# tle984x register map
Vendor: Infineon; File version: 1.9.5
CPU: CM0 r2p1, little endian, no MPU, no FPU, 2 interrupt priority bits
Registers are 32-bit, read-write, reset 0x0 unless marked. A register's access mark holds for its fields unless they carry their own. Offsets are from the block's base; [hi:lo] are bit positions; {n}, {i} and the like mark numbered series; 'fields as' and 'values as' point back to an identical list.

## CCU6 — Capture/Compare Unit 6 (CCU6) registers
Base 0x4000C000
0x00 CC63R 16-bit ro — Capture/compare for channel CC63 register
  [15:0] CCV — Channel CC63 compare value low byte
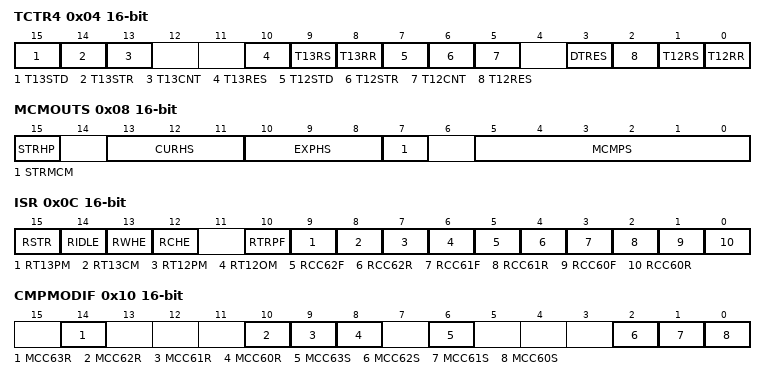
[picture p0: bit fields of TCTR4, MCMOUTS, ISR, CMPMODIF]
0x04 TCTR4 16-bit — Timer control 4 register
  [15] T13STD wo — Timer T13 shadow transfer disable
    0=No_action; 1=STE13_reset (STE13 is reset without triggering the shadow transfer)
  [14] T13STR wo — Timer T13 shadow transfer request
    0=No_action; 1=STE13_set (STE13 is set, enabling the shadow transfer)
  [13] T13CNT wo — Timer T13 count event
    0=No_action; 1=Count (If enabled (PISEL2), timer T13 counts one step)
  [10] T13RES wo — Timer T13 reset
    0=No effect on T13; 1=Zero (The T13 counter register is reset to zero. The switching of the output signals is according to the switching rules. Setting of T13RES has no impact on bit T13R)
  [9] T13RS wo — Timer T13 run set
    0=No_influence (T13R is not influenced); 1=T13R_set (T13R is set, T13 counts)
  [8] T13RR wo — Timer T13 run reset
    0=No_influence (T13R is not influenced); 1=T13R_cleared (T13R is cleared, T13 stops counting)
  [7] T12STD wo — Timer T12 shadow transfer disable
    0=No_action; 1=STE12_reset (STE12 is reset without triggering the shadow transfer)
  [6] T12STR wo — Timer T12 shadow transfer request
    0=No_action; 1=STE12_set (STE12 is set, enabling the shadow transfer)
  [5] T12CNT wo — Timer T12 count event
    0=No_action; 1=Count (If enabled (PISEL2), timer T12 counts one step)
  [3] DTRES wo — Dead-time counter reset
    0=No effect on the dead-time counters; 1=Zero (The three dead-time counter channels are reset to zero)
  [2] T12RES wo — Timer T12 reset
    0=No effect on T12; 1=Zero (The T12 counter register is reset to zero. The switching of the output signals is according to the switching rules; setting of T12RES has no impact on bit T12R)
  [1] T12RS wo — Timer T12 run set
    0=No_influence (T12R is not influenced); 1=T12R_set (T12R is set, T12 counts)
  [0] T12RR wo — Timer T12 run reset
    0=No_influence (T12R is not influenced); 1=T12R_cleared (T12R is cleared, T12 stops counting)
0x08 MCMOUTS 16-bit — Multi-channel mode output shadow register
  [15] STRHP wo — Shadow transfer request for the Hall pattern
    0=By_hardware (The bit fields CURH and EXPH are updated according to the defined hardware action. The write access to bit fields CURHS and EXPHS does not modify the bit fields CURH and EXPH); 1=By_software (The bit fields CURH and EXPH are updated by the value written to the bit fields CURHS and EXPHS)
  [13:11] CURHS — Current Hall pattern shadow
  [10:8] EXPHS — Expected Hall pattern shadow
  [7] STRMCM wo — Shadow transfer request for MCMPS
    0=By_hardware (Bit field MCMP is updated according to the defined hardware action. The write access to bit field MCMPS does not modify bit field MCMP); 1=By_software (Bit field MCMP is updated by the value written to bit field MCMPS)
  [5:0] MCMPS — Multi-channel PWM pattern shadow
0x0C ISR 16-bit — Capture/compare interrupt status reset register
  [15] RSTR wo — Reset STR flag
    0=No_action; 1=Reset (Bit STR in register IS will be reset)
  [14] RIDLE wo — Reset IDLE flag
    0=No_action; 1=Reset (Bit IDLE in register IS will be reset)
  [13] RWHE wo — Reset wrong Hall event flag
    0=No_action; 1=Reset (Bit WHE in register IS will be reset)
  [12] RCHE wo — Reset correct Hall event flag
    0=No_action; 1=Reset (Bit CHE in register IS will be reset)
  [10] RTRPF wo — Reset trap flag
    0=No_action; 1=Reset (Bit TRPF in register IS will be reset (not taken into account while input CTRAP= 0 and TRPPEN = 1))
  [9] RT13PM wo — Reset timer T13 period-Match flag
    0=No_action; 1=Reset (Bit T13PM in register IS will be reset)
  [8] RT13CM wo — Reset timer T13 compare-match flag
    0=No_action; 1=Reset (Bit T13CM in register IS will be reset)
  [7] RT12PM wo — Reset timer T12 period-match flag
    0=No_action; 1=Reset (Bit T12PM in register IS will be reset)
  [6] RT12OM wo — Reset timer T12 one-match flag
    0=No_action; 1=Reset (Bit T12OM in register IS will be reset)
  [5] RCC62F wo — Reset capture, compare-match falling edge flag
    0=No_action; 1=Reset (Bit CC62F in register IS will be reset)
  [4] RCC62R wo — Reset capture, compare-match rising edge flag
    0=No_action; 1=Reset (Bit CC62R in register IS will be reset)
  [3] RCC61F wo — Reset capture, compare-match falling edge flag
    0=No_action; 1=Reset (Bit CC61F in register IS will be reset)
  [2] RCC61R wo — Reset capture, compare-match rising edge Flag
    0=No_action; 1=Reset (Bit CC61R in register IS will be reset)
  [1] RCC60F wo — Reset capture, compare-match falling edge flag
    0=No_action; 1=Reset (Bit CC60F in register IS will be reset)
  [0] RCC60R wo — Reset capture, compare-match rising edge flag
    0=No_action; 1=Reset (Bit CC60R in register IS will be reset)
0x10 CMPMODIF 16-bit — Compare state modification register
  [14] MCC63R wo — Capture/compare status modification bits (reset)
  [10] MCC62R wo — Capture/compare status modification bit 2 (reset)
  [9] MCC61R wo — Capture/compare status modification bit 1 (reset)
  [8] MCC60R wo — Capture/compare status modification bit 0 (reset)
  [6] MCC63S wo — Capture/compare status modification bits (set)
  [2] MCC62S wo — Capture/compare status modification bit 2 (set)
  [1] MCC61S wo — Capture/compare status modification bit 1 (set)
  [0] MCC60S wo — Capture/compare status modification bit 0 (set)
0x14 CC60SR 16-bit — Capture/compare shadow register for channel CC60 register
  [15:0] CCS — Shadow register for channel 0 capture/compare value
0x18 CC61SR 16-bit — Capture/compare shadow register for channel CC61 register
  [15:0] CCS — Shadow register for channel 1 capture/compare value
0x1C CC62SR 16-bit — Capture/compare shadow register for channel CC62 register
  [15:0] CCS — Shadow register for channel 2 capture/compare value
0x20 CC63SR 16-bit — Capture/compare shadow for channel CC63 register
  [15:0] CCS — Shadow register for channel CC63 compare value
0x24 T12PR 16-bit — Timer T12 period register
  [15:0] T12PV — T12 period value
0x28 T13PR 16-bit — Timer T13 period register
  [15:0] T13PV — T13 period value
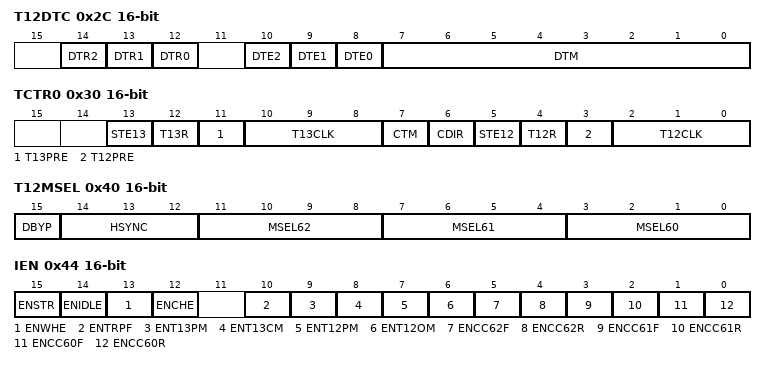
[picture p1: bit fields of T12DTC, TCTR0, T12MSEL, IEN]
0x2C T12DTC 16-bit — Dead-time control register for timer T12 low register
  [14] DTR2 ro — Dead-time run indication bit 2
    0=Zero (The value of the corresponding dead-time counter channel is 0); 1=Not_zero (The value of the corresponding dead-time counter channel is not 0)
  [13] DTR1 ro — Dead-time run indication bit 1
    values as DTR2
  [12] DTR0 ro — Dead-time run indication bit 0
    values as DTR2
  [10] DTE2 — Dead-time enable bit 2
    0=DISABLED (Dead-time generation is disabled. The corresponding outputs switch from the passive state to the active state (according to the actual compare status) without any delay); 1=ENABLED (Dead-time generation is enabled. The corresponding outputs switch from the passive state to the active state (according to the compare status) with the delay programmed in bit field DTM)
  [9] DTE1 — Dead-time enable bit 1
    values as DTE2
  [8] DTE0 — Dead-time enable bit 0
    values as DTE2
  [7:0] DTM — Dead-time
0x30 TCTR0 16-bit — Timer control 0 register
  [13] STE13 ro — Timer T13 shadow transfer enable
    0=DISABLED (The shadow register transfer is disabled); 1=ENABLED (The shadow register transfer is enabled)
  [12] T13R ro — Timer T13 run bit
    0=Stop (Timer T13 is stopped); 1=Run (Timer T13 is running)
  [11] T13PRE — Timer T13 prescaler bit
    0=DISABLED (The additional prescaler for T13 is disabled); 1=ENABLED (The additional prescaler for T13 is enabled)
  [10:8] T13CLK — Timer T13 input clock Select
    0=fT13 = fCCU; 1=fT13 = fCCU / 2; 2=fT13 = fCCU / 4; 3=fT13 = fCCU / 8; 4=fT13 = fCCU / 16; 5=fT13 = fCCU/ 32; 6=fT13 = fCCU / 64; 7=fT13 = fCCU / 128
  [7] CTM — T12 operating mode
    0=Edge_aligned_mode (T12 always counts up and continues counting from zero after reaching the period value); 1=Center_aligned_mode (T12 counts down after detecting a period-match and counts up after detecting a one-match)
  [6] CDIR ro — Count direction of timer T12
    0=UP (T12 counts up); 1=DOWN (T12 counts down)
  [5] STE12 ro — Timer T12 shadow transfer enable
    values as STE13
  [4] T12R ro — Timer T12 run bit
    0=Stop (Timer T12 is stopped); 1=Run (Timer T12 is running)
  [3] T12PRE — Timer T12 prescaler bit
    0=DISABLED (The additional prescaler for T12 is disabled); 1=ENABLED (The additional prescaler for T12 is enabled)
  [2:0] T12CLK — Timer T12 input clock select
    0=fT12 = fCCU; 1=fT12 = fCCU / 2; 2=fT12 = fCCU / 4; 3=fT12 = fCCU / 8; 4=fT12 = fCCU / 16; 5=fT12 = fCCU / 32; 6=fT12 = fCCU / 64; 7=fT12 = fCCU / 128
0x34 CC60R 16-bit ro — Capture/compare register for channel CC60 register
  [15:0] CCV — Channel 0 capture/compare value
0x38 CC61R 16-bit ro — Capture/compare register for channel CC61 register
  [15:0] CCV — Channel 1 capture/compare value
0x3C CC62R 16-bit ro — Capture/compare register for channel CC62 register
  [15:0] CCV — Channel 2 capture/compare value
0x40 T12MSEL 16-bit — T12 capture/compare mode select register
  [15] DBYP — Delay bypass
    0=Not_active (The delay bypass is not active. The dead-time counter DTC0 is generating a delay after the source signal becomes active); 1=Active (The delay bypass is active. The dead-time counter DTC0 is not used by the sampling of the Hall pattern)
  [14:12] HSYNC — Hall synchronization
    0=Any (Any edge at one of the inputs CCPOSx (x = 0, 1, 2) triggers the sampling); 1=T13_compare_match (A T13 compare-match triggers the sampling); 2=T13_period_match (A T13 period-match triggers the sampling); 3=Hall (The Hall sampling triggered by hardware sources is switched off); 4=T12_period_match (A T12 period-match (while counting up) triggers the sampling); 5=T12_one_match (A T12 one-match (while counting down) triggers the sampling); 6=T12_compare_match_UP (A T12 compare-match of channel 0 (while counting up) triggers the sampling); 7=T12_compare_match_DOWN (A T12 compare-match of channel 0 (while counting down) triggers the sampling)
  [11:8] MSEL62 — Capture/compare mode selection
    0=Compare outputs disabled, pins CC6n and COUT6n can be used for I/O. No capture action; 1=Pin_CC6n_pin_COUT6n (Compare output on pin CC6n, pin COUT6n can be used for I/O. No capture action); 2=Pin_COUT6n_pin_CC6n (Compare output on pin COUT6n, pin CC6n can be used for I/O. No capture action); 3=Pins_COUT6n_and_CC6n (Compare output on pins COUT6n and CC6n); {v}=Double_register_Capture_modes (See Table "Double-register capture modes") (v=4..7); 8=Hall_sensor_mode (See Table "Combined T12 modes". In order to enable the hall edge detection, all three MSEL6x must be programmed to Hall sensor mode); 9=Hysteresis_like_mode (See Table "Combined T12 modes"); {v}=Multi_input_Capture_modes (See Table "Multi-input capture modes") (v=10..15)
  [7:4] MSEL61 — Capture/compare mode selection
    0=Compare outputs disabled, compare outputs disabled, pins CC6n and COUT6n can be used for I/O. No capture action.; 1=Pin_CC6n_pin_COUT6n (Compare output on pin CC6n, pin COUT6n can be used for I/O; no capture action); 2=Pin_COUT6n_pin_CC6n (Pin CC6n, compare output on pin COUT6n, pin CC6n can be used for I/O. No capture action); 3=Pins_COUT6n_and_CC6n (Compare output on pins COUT6n and CC6n); {v}=Double_register_Capture_modes (See Table "Double-register capture modes") (v=4..7); 8=Hall_sensor_mode (See Table "Combined T12 modes". In order to enable the hall edge detection, all three MSEL6x must be programmed to Hall sensor mode); 9=Hysteresis_like_mode (See Table "Combined T12 modes"); {v}=Multi_input_Capture_modes (See Table "Multi-input capture modes") (v=10..15)
  [3:0] MSEL60 — Capture/compare mode selection
    0=Compare outputs disabled, pins CC6n and COUT6n can be used for I/O. No capture action; 1=Pin_CC6n_pin_COUT6n (Compare output on pin CC6n, pin COUT6n can be used for I/O. No capture action); 2=Pin_COUT6n_pin_CC6n (Compare output on pin COUT6n, pin CC6n can be used for I/O. No capture action); 3=Pins_COUT6n_and_CC6n (Compare output on pins COUT6n and CC6n); {v}=Double_register_Capture_modes (See Table "Register capture modes") (v=4..7); 8=Hall_sensor_mode (See Table "Register capture modes". In order to enable the hall edge detection, all three MSEL6x must be programmed to Hall sensor mode); 9=Hysteresis_like_mode (See Table "Combined T12 modes"); {v}=Multi_input_Capture_modes (See Table "Multi-input capture modes") (v=10..15)
0x44 IEN 16-bit — Capture/compare interrupt enable register
  [15] ENSTR — Enable multi-channel mode shadow transfer interrupt
    0=No interrupt will be generated if the set condition for bit STR in register IS occurs; 1=Interrupt (An interrupt will be generated if the set condition for bit STR in register IS occurs. The interrupt line that will be activated is selected by bit field INPCHE)
  [14] ENIDLE — Enable idle
    0=IDLE_not_set (The bit IDLE is not automatically set when a wrong hall event is detected); 1=IDLE_set (The bit IDLE is automatically set when a wrong hall event is detected)
  [13] ENWHE — Enable interrupt for wrong Hall Event
    0=No interrupt will be generated if the set condition for bit WHE in register IS occurs; 1=Interrupt (An interrupt will be generated if the set condition for bit WHE in register IS occurs. The interrupt line that will be activated is selected by bit field INPERR)
  [12] ENCHE — Enable interrupt for correct Hall Event
    0=No interrupt will be generated if the set condition for bit CHE in register IS occurs; 1=Interrupt (An interrupt will be generated if the set condition for bit CHE in register IS occurs. The interrupt line that will be activated is selected by bit field INPCHE)
  [10] ENTRPF — Enable interrupt for trap flag
    0=No interrupt will be generated if the set condition for bit TRPF in register IS occurs; 1=Interrupt (An interrupt will be generated if the set condition for bit TRPF in register IS occurs. The interrupt line that will be activated is selected by bit field INPERR)
  [9] ENT13PM — Enable interrupt for T13 period-match
    0=No interrupt will be generated if the set condition for bit T13PM in register IS occurs; 1=Interrupt (An interrupt will be generated if the set condition for bit T13PM in register IS occurs. The interrupt line that will be activated is selected by bit field INPT13)
  [8] ENT13CM — Enable interrupt for T13 compare-match
    0=No interrupt will be generated if the set condition for bit T13CM in register IS occurs; 1=Interrupt (An interrupt will be generated if the set condition for bit T13CM in register IS occurs. The interrupt line that will be activated is selected by bit field INPT13)
  [7] ENT12PM — Enable interrupt for T12 period-match
    0=No interrupt will be generated if the set condition for bit T12PM in register IS occurs; 1=Interrupt (An interrupt will be generated if the set condition for bit T12PM in register IS occurs. The interrupt line that will be activated is selected by bit field INPT12)
  [6] ENT12OM — Enable interrupt for T12 one-match
    0=No interrupt will be generated if the set condition for bit T12OM in register IS occurs; 1=Interrupt (An interrupt will be generated if the set condition for bit T12OM in register IS occurs. The interrupt line that will be activated is selected by bit field INPT12)
  [5] ENCC62F — Capture, compare-match falling edge interrupt enable for channel 2
    0=No interrupt will be generated if the set condition for bit CC62F in register IS occurs; 1=Interrupt (An interrupt will be generated if the set condition for bit CC62F in register IS occurs. The interrupt line that will be activated is selected by bit field INPCC62)
  [4] ENCC62R — Capture, compare-match rising edge interrupt enable for channel 2
    0=No interrupt will be generated if the set condition for bit CC62R in register IS occurs; 1=Interrupt (An interrupt will be generated if the set condition for bit CC62R in register IS occurs. The interrupt line that will be activated is selected by bit field INPCC62)
  [3] ENCC61F — Capture, compare-match falling edge interrupt enable for channel 1
    0=No interrupt will be generated if the set condition for bit CC61F in register IS occurs; 1=Interrupt (An interrupt will be generated if the set condition for bit CC61F in register IS occurs. The interrupt line that will be activated is selected by bit field INPCC61)
  [2] ENCC61R — Capture, compare-match rising edge interrupt enable for channel 1
    0=No interrupt will be generated if the set condition for bit CC61R in register IS occurs; 1=Interrupt (An interrupt will be generated if the set condition for bit CC61R in register IS occurs. The interrupt line that will be activated is selected by bit field INPCC61)
  [1] ENCC60F — Capture, compare-match falling edge interrupt enable for channel 0
    0=No interrupt will be generated if the set condition for bit CC60F in register IS occurs; 1=Interrupt (An interrupt will be generated if the set condition for bit CC60F in register IS occurs. The interrupt line that will be activated is selected by bit field INPCC60)
  [0] ENCC60R — Capture, compare-match rising edge interrupt enable for channel 0
    0=No interrupt will be generated if the set condition for bit CC60R in register IS occurs; 1=Interrupt (An interrupt will be generated if the set condition for bit CC60R in register IS occurs. The interrupt line that will be activated is selected by bit field INPCC60)
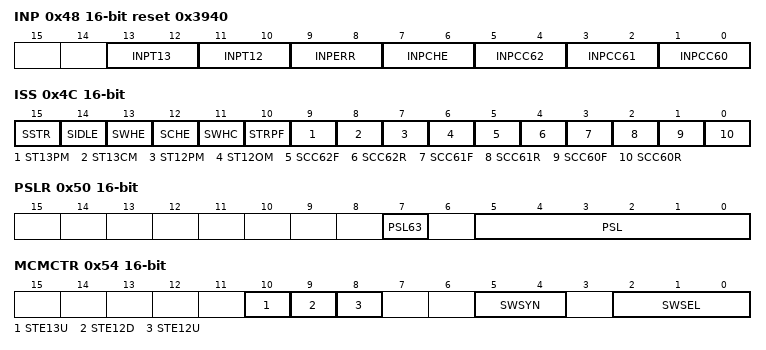
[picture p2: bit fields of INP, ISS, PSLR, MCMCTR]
0x48 INP 16-bit reset 0x3940 — Capture/compare interrupt node pointer register
  [all] fields
    {v}=SR{v} (Interrupt output line SR{v} is selected) (v=0..3)
  [13:12] INPT13 — Interrupt node pointer for timer T13 interrupts
  [11:10] INPT12 — Interrupt node pointer for timer T12 interrupts
  [9:8] INPERR — Interrupt node pointer for error interrupts
  [7:6] INPCHE — Interrupt node pointer for the CHE interrupt
  [5:4] INPCC62 — Interrupt node pointer for channel 2 interrupts
  [3:2] INPCC61 — Interrupt node pointer for channel 1 interrupts
  [1:0] INPCC60 — Interrupt node pointer for channel 0 interrupts
0x4C ISS 16-bit wo — Capture/compare interrupt status set register
  [15] SSTR — Set STR flag
    0=No_action; 1=Set (Bit STR in register IS will be set)
  [14] SIDLE — Set IDLE flag
    0=No_action; 1=Set (Bit IDLE in register IS will be set)
  [13] SWHE — Set wrong Hall event flag
    0=No_action; 1=Set (Bit WHE in register IS will be set)
  [12] SCHE — Set correct Hall event flag
    0=No_action; 1=Set (Bit CHE in register IS will be set)
  [11] SWHC — Software Hall compare
    0=No_action; 1=Set (The Hall compare action is triggered)
  [10] STRPF — Set trap flag
    0=No_action; 1=Set (Bits TRPF and TRPS in register IS will be set)
  [9] ST13PM — Set timer T13 period-match flag
    0=No_action; 1=Set (Bit T13PM in register IS will be set)
  [8] ST13CM — Set timer T13 compare-match flag
    0=No_action; 1=Set (Bit T13CM in register IS will be set)
  [7] ST12PM — Set timer T12 period-match flag
    0=No_action; 1=Set (Bit T12PM in register IS will be set)
  [6] ST12OM — Set timer T12 one-match flag
    0=No_action; 1=Set (Bit T12OM in register IS will be set)
  [5] SCC62F — Set capture, compare-match falling edge flag
    0=No_action; 1=Set (Bit CC62F in register IS will be set)
  [4] SCC62R — Set capture, compare-match rising edge flag
    0=No_action; 1=Set (Bit CC62R in register IS will be set)
  [3] SCC61F — Set capture, compare-match falling edge flag
    0=No_action; 1=Set (Bit CC61F in register IS will be set)
  [2] SCC61R — Set capture, compare-match rising edge flag
    0=No_action; 1=Set (Bit CC61R in register IS will be set)
  [1] SCC60F — Set capture, compare-match falling edge flag
    0=No_action; 1=Set (Bit CC60F in register IS will be set)
  [0] SCC60R — Set capture, compare-match rising edge flag
    0=No_action; 1=Set (Bit CC60R in register IS will be set)
0x50 PSLR 16-bit — Passive state level register
  [7] PSL63 — Passive state level of output COUT63
    0=Level_0 (The passive level is 0); 1=Level_1 (The passive level is 1)
  [5:0] PSL — Compare outputs passive state level
    values as PSL63
0x54 MCMCTR 16-bit — Multi-channel mode control register
  [10] STE13U — Shadow transfer enable for T13 upcounting
    0=No_action; 1=ENABLED (The T13_ST shadow transfer mechanism is enabled if MCMEN = 1)
  [9] STE12D — Shadow transfer Enable for T12 downcounting
    0=No_action; 1=ENABLED (The T12_ST shadow transfer mechanism is enabled if MCMEN = 1)
  [8] STE12U — Shadow transfer enable for T12 upcounting
    values as STE12D
  [5:4] SWSYN — Switching Synchronization
    0=Direct (The trigger event directly causes the shadow transfer); 1=T13 zero-match triggers the shadow transfer; 2=T12_zero_match (A T12 zero-match (while counting up) triggers the shadow transfer)
  [2:0] SWSEL — Switching selection
    0=No_request (No trigger request will be generated); 1=Correct_pattern (Correct hall pattern on CCPOSx detected); 2=T13 period-match detected (while counting up); 3=T12 one-match (while counting down); 4=T12 channel 1 compare-match detected (phase delay function); 5=T12 period match detected (while counting up) else reserved, no trigger request will be generated
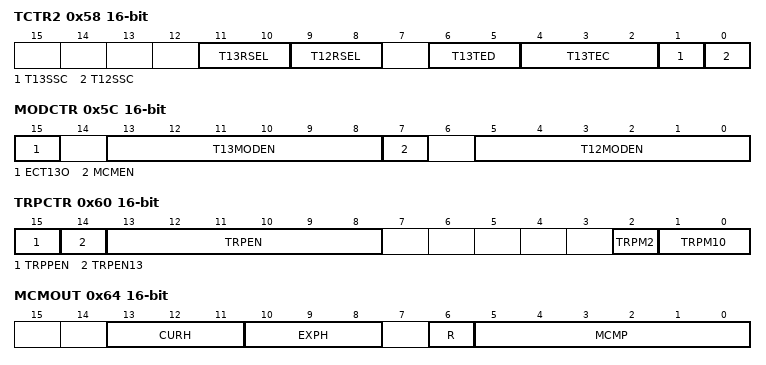
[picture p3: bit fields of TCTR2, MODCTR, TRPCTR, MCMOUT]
0x58 TCTR2 16-bit — Timer control 2 register
  [11:10] T13RSEL — Timer T13 external run selection
    0=DISABLED (The external setting of T13R is disabled); 1=Rising_edge (Bit T13R is set if a rising edge of signal T13HR is detected); 2=Falling_edge (Bit T13R is set if a falling edge of signal T13HR is detected); 3=Edge (Bit T13R is set if an edge of signal T13HR is detected)
  [9:8] T12RSEL — Timer T12 external run selection
    0=DISABLED (The external setting of T12R is disabled); 1=Rising_edge (Bit T12R is set if a rising edge of signal T12HR is detected); 2=Falling_edge (Bit T12R is set if a falling edge of signal T12HR is detected); 3=Edge (Bit T12R is set if an edge of signal T12HR is detected)
  [6:5] T13TED — Timer T13 trigger event direction
    0=No_action; 1=Up (While T12 is counting up); 2=Down (While T12 is counting down); 3=Independent on the count direction of T12
  [4:2] T13TEC — T13 trigger event control
    0=No_action; 1=Channel_0 (Set T13R on a T12 compare event on channel 0); 2=Channel_1 (Set T13R on a T12 compare event on channel 1); 3=Channel_2 (Set T13R on a T12 compare event on channel 2); 4=Channel_0_1_2 (Set T13R on any T12 compare event on the channels 0, 1, or 2); 5=Period_match (Set T13R upon a period-match of T12); 6=Zero_match (Set T13R upon a zero-match of T12 (while counting up)); 7=CCPOSx (Set T13R on any edge of inputs CCPOSx)
  [1] T13SSC — Timer T13 single shot control
    0=No_action (No hardware action on T13R); 1=ENABLED (The single-shot mode is enabled, the bit T13R is reset by hardware if T13 reaches its period value. In parallel to the reset action of bit T13R, the bit CC63ST is reset)
  [0] T12SSC — Timer T12 single shot control
    0=DISABLED (The single-shot mode is disabled, no hardware action on T12R); 1=ENABLED (The single shot mode is enabled, the bit T12R is reset by hardware if:)
0x5C MODCTR 16-bit — Modulation control register
  [15] ECT13O — Enable compare timer T13 output
    0=DISABLED (The alternate output function COUT63 is disabled); 1=ENABLED (The alternate output function COUT63 is enabled for the PWM signal generated by T13)
  [13:8] T13MODEN — T13 modulation enable
    0=DISABLED (The modulation of the corresponding output signal by a T13 PWM pattern is disabled); 1=ENABLED (The modulation of the corresponding output signal by a T13 PWM pattern is enabled)
  [7] MCMEN — Multi-channel mode enable
    0=DISABLED (The modulation of the corresponding output signal by a multi-channel pattern according to bit field MCMOUT is disabled); 1=ENABLED (The modulation of the corresponding output signal by a multi-channel pattern according to bit field MCMOUT is enabled)
  [5:0] T12MODEN — T12 modulation enable
    0=DISABLED (The modulation of the corresponding output signal by a T12 PWM pattern is disabled); 1=ENABLED (The modulation of the corresponding output signal by a T12 PWM pattern is enabled)
0x60 TRPCTR 16-bit — Trap control register
  [15] TRPPEN — Trap pin enable
    0=DISABLED (The trap functionality based on the input pin CTRAP is disabled. A trap can only be generated by software by setting bit TRPF); 1=ENABLED (The trap functionality based on the input pin CTRAP is enabled. A trap can be generated by software by setting bit TRPF or by CTRAP = 0)
  [14] TRPEN13 — Trap enable control for timer T13
    0=DISABLED (The trap functionality for T13 is disabled; timer T13 (if selected and enabled) provides PWM functionality even while TRPS = 1); 1=ENABLED (The trap functionality for T13 is enabled; the timer T13 PWM output signal is set to the passive state while TRPS = 1)
  [13:8] TRPEN — Trap enable control
    0=DISABLED (The trap functionality of the corresponding output signal is disabled; the output state is independent from bit TRPS); 1=ENABLED (The trap functionality of the corresponding output signal is enabled; the output is set to the passive state while TRPS = 1)
  [2] TRPM2 — Trap mode control bit 2
    0=Hardware_reset; 1=Software_reset
  [1:0] TRPM10 — Trap mode control bits 1, 0
    0=T12_zero_match (The trap state is left (return to normal operation according to TRPM2) when a zero-match of T12 (while counting up) is detected (synchronization to T12)); 1=T13_zero_match (The trap state is left (return to normal operation according to TRPM2) when a zero-match of T13 is detected (synchronization to T13)); 3=Immediately (The trap state is left (return to normal operation according to TRPM2) immediately without any synchronization to T12 or T13)
0x64 MCMOUT 16-bit ro — Multi-channel mode output register
  [13:11] CURH — Current Hall pattern
  [10:8] EXPH — Expected Hall pattern
  [6] R — Reminder Flag
    0=No shadow transfer, currently, no shadow transfer from MCMPS to MCMP is requested; 1=Shadow_transfer (A shadow transfer from MCMPS to MCMP has been requested by the selected trigger source, but it has not yet been executed, because the selected synchronization condition has not yet occurred)
  [5:0] MCMP — Multi-channel PWM pattern
    0=Passive (The output is set to the passive state. The PWM generated by T12 or T13 is not taken into account); 1=PWM (The output can deliver the PWM generated by T12 or T13 (according to register MODCTR))
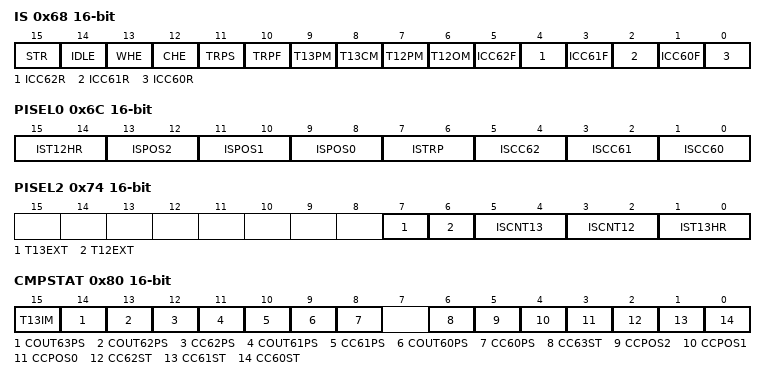
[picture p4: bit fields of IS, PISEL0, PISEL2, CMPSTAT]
0x68 IS 16-bit ro — Capture/compare interrupt status register
  [15] STR — Multi-channel mode shadow transfer request
    0=No (The shadow transfer has not yet taken place); 1=Yes (The shadow transfer has taken place)
  [14] IDLE — IDLE state
    0=No_action; 1=Idle (Bit field MCMP is cleared and held to 0, the selected outputs are set to passive state)
  [13] WHE — Wrong Hall event
    0=Not_detected (A transition to a wrong Hall event (not the expected one) has not yet been detected since this bit has been reset for the last time); 1=Detected (A transition to a wrong Hall event (not the expected one) has been detected)
  [12] CHE — Correct Hall event
    0=Not_detected (A transition to a correct (= expected) Hall event has not yet been detected since this bit has been reset for the last time); 1=Detected (A transition to a correct (= expected) Hall event has been detected)
  [11] TRPS — Trap state
    0=Not_active (The trap state is not active); 1=Active (The trap state is active. Bit TRPS is set while bit TRPF = 1. It is reset according to the mode selected in register TRPCTR)
  [10] TRPF — Trap flag
    0=Not_detected (The trap condition has not been detected); 1=Detected (The trap condition has been detected (input CTRAP has been 0 or by software))
  [9] T13PM — Timer T13 period-match flag
    0=Not_detected (A timer T13 period-match has not yet been detected since this bit has been reset for the last time); 1=Detected (A timer T13 period-match has been detected)
  [8] T13CM — Timer T13 compare-match flag
    0=Not_detected (A timer T13 compare-match has not yet been detected since this bit has been reset for the last time); 1=Detected (A timer T13 compare-match has been detected)
  [7] T12PM — Timer T12 period-match flag
    0=Not_detected (A timer T12 period-match (while counting up) has not yet been detected since this bit has been reset for the last time); 1=Detected (A timer T12 period-match (while counting up) has been detected)
  [6] T12OM — Timer T12 one-match flag
    0=Not_detected (A timer T12 one-match (while counting down) has not yet been detected since this bit has been reset for the last time); 1=Detected (A timer T12 one-match (while counting down) has been detected)
  [5] ICC62F — Capture, compare-match falling edge flag
    0=Not_occurred (The event has not yet occurred since this bit has been reset for the last time); 1=Detected (The event described above has been detected)
  [4] ICC62R — Capture, compare-match rising edge flag
    values as ICC62F
  [3] ICC61F — Capture, compare-match falling edge flag
    values as ICC62F
  [2] ICC61R — Capture, compare-match rising edge flag
    values as ICC62F
  [1] ICC60F — Capture, compare-match falling edge flag
    values as ICC62F
  [0] ICC60R — Capture, compare-match rising edge flag
    values as ICC62F
0x6C PISEL0 16-bit — Port input select 0 register
  [15:14] IST12HR — Input select for T12HR
    0=T12HRA (Either signal T12HRA (if T12EXT = 0) or T12HRE (if T12EXT = 1) is selected); 1=T12HRB (Either signal T12HRB (if T12EXT = 0) or T12HRF (if T12EXT = 1) is selected); 2=T12HRC (Either signal T12HRC (if T12EXT = 0) or T12HRG (if T12EXT = 1) is selected); 3=T12HRD (Either signal T12HRD (if T12EXT = 0) or T12HRH (if T12EXT = 1) is selected)
  [13:12] ISPOS2 — Input select for CCPOS2
    {v}=CCPOS2_{v} (The input pin for CCPOS2_{v}) (v=0..3)
  [11:10] ISPOS1 — Input select for CCPOS1
    {v}=CCPOS1_{v} (The input pin for CCPOS1_{v}) (v=0..3)
  [9:8] ISPOS0 — Input select for CCPOS0
    {v}=CCPOS0_{v} (The input pin for CCPOS0_{v}) (v=0..3)
  [7:6] ISTRP — Input select for CTRAP
    0=CTRAP_0 (The input pin for CTRAP_0); 1=CTRAP_1 (The input pin for CTRAP_1); 2=CTRAP_2 (The input pin for CTRAP_2); 3=CTRAP_3 (Signal from differential units)
  [5:4] ISCC62 — Input select for CC62
    0=CC62_0 (The input pin for CC62_0); 1=CC62_1 (The input pin for CC62_1)
  [3:2] ISCC61 — Input select for CC61
    0=CC61_0 (The input pin for CC61_0); 1=CC61_1 (The input pin for CC61_1)
  [1:0] ISCC60 — Input select for CC60
    0=CC60_0 (The input pin for CC60_0); 1=CC60_1 (The input pin for CC60_1)
0x74 PISEL2 16-bit — Port input select 2 register
  [7] T13EXT — Extension for T13HR inputs
    0=T13HR_D_A_ (T13HR[D:A], one of the signals T13HR[D:A] is selected); 1=T13HR_H_E_ (T13HR[H:E], one of the signals T13HR[H:E] is selected)
  [6] T12EXT — Extension for T12HR inputs
    0=T12HR_D_A_ (T12HR[D:A], one of the signals T12HR[D:A] is selected); 1=T12HR_H_E_ (T12HR[H:E], one of the signals T12HR[H:E] is selected)
  [5:4] ISCNT13 — Input select for T13 counting input
    0=T13_prescaler (The T13 prescaler generates the counting events. Bit TCTR4.T13CNT is not taken into account); 1=TCTR4_T13CNT (Bit TCTR4.T13CNT written with 1 is a counting event. The T13 prescaler is not taken into account); 2=Rising_edge (The timer T13 is counting each rising edge detected in the selected T13HR signal); 3=Falling_edge (The timer T13 is counting each falling edge detected in the selected T13HR signal)
  [3:2] ISCNT12 — Input select for T12 counting input
    0=T12_prescaler (The T12 prescaler generates the counting events. Bit TCTR4.T12CNT is not taken into account); 1=TCTR4_T12CNT (Bit TCTR4.T12CNT written with 1 is a counting event. The T12 prescaler is not taken into account); 2=Rising_edge (The timer T12 is counting each rising edge detected in the selected T12HR signal); 3=Falling_edge (The timer T12 is counting each falling edge detected in the selected T12HR signal)
  [1:0] IST13HR — Input select for T13HR
    0=T13HRA (Either signal T13HRA (if T13EXT = 0) or T13HRE (if T13EXT = 1) is selected); 1=T13HRB (Either signal T13HRB (if T13EXT = 0) or T13HRF (if T13EXT = 1) is selected); 2=T13HRC (Either signal T13HRC (if T13EXT = 0) or T13HRG (if T13EXT = 1) is selected); 3=T13HRD (Either signal T13HRD (if T13EXT = 0) or T13HRH (if T13EXT = 1) is selected)
0x78 T12 16-bit — Timer T12 counter register
  [15:0] T12CV — Timer T12 counter value
0x7C T13 16-bit — Timer T13 counter register
  [15:0] T13CV — Timer T13 counter value
0x80 CMPSTAT 16-bit — Compare state register
  [15] T13IM — T13 inverted modulation
    0=Not_inverted (T13 output is not inverted); 1=Inverted (T13 output is inverted for further modulation)
  [14] COUT63PS — Passive state select for compare outputs
    0=Zero (The corresponding compare output drives passive level while CC6xST is 0); 1=One (The corresponding compare output drives passive level while CC6xST is 1)
  [13] COUT62PS — Passive state select for compare outputs
    values as COUT63PS
  [12] CC62PS — Passive state select for compare outputs
    values as COUT63PS
  [11] COUT61PS — Passive state select for compare outputs
    values as COUT63PS
  [10] CC61PS — Passive state select for compare outputs
    values as COUT63PS
  [9] COUT60PS — Passive state select for compare outputs
    values as COUT63PS
  [8] CC60PS — Passive state select for compare outputs
    values as COUT63PS
  [6] CC63ST ro — Capture/compare state bits
    0=Less (In compare mode, the timer count is less than the compare value. In capture mode, the selected edge has not yet been detected since the bit has been reset by software the last time); 1=Greater (In compare mode, the counter value is greater than or equal to the compare value. In capture mode, the selected edge has been detected)
  [5] CCPOS2 ro — Sampled Hall pattern bit 2
    0=Zero (The input CCPOS2 has been sampled as 0); 1=One (The input CCPOS2 has been sampled as 1)
  [4] CCPOS1 ro — Sampled Hall pattern bit 1
    0=Zero (The input CCPOS1 has been sampled as 0); 1=One (The input CCPOS1 has been sampled as 1)
  [3] CCPOS0 ro — Sampled Hall pattern bit 0
    0=Zero (The input CCPOS0 has been sampled as 0); 1=One (The input CCPOS0 has been sampled as 1)
  [2] CC62ST ro — Capture/compare state bits
    values as CC63ST
  [1] CC61ST ro — Capture/compare state bits
    0=Less (In compare mode, the timer count is less than the compare value. In capture mode, the selected edge has not yet been detected since the bit has been reset by software the last time); 1=Greater (In compare mode, the counter value is greater than or equal to the compare value; In capture mode, the selected edge has been detected)
  [0] CC60ST ro — Capture/compare state bits
    values as CC63ST
